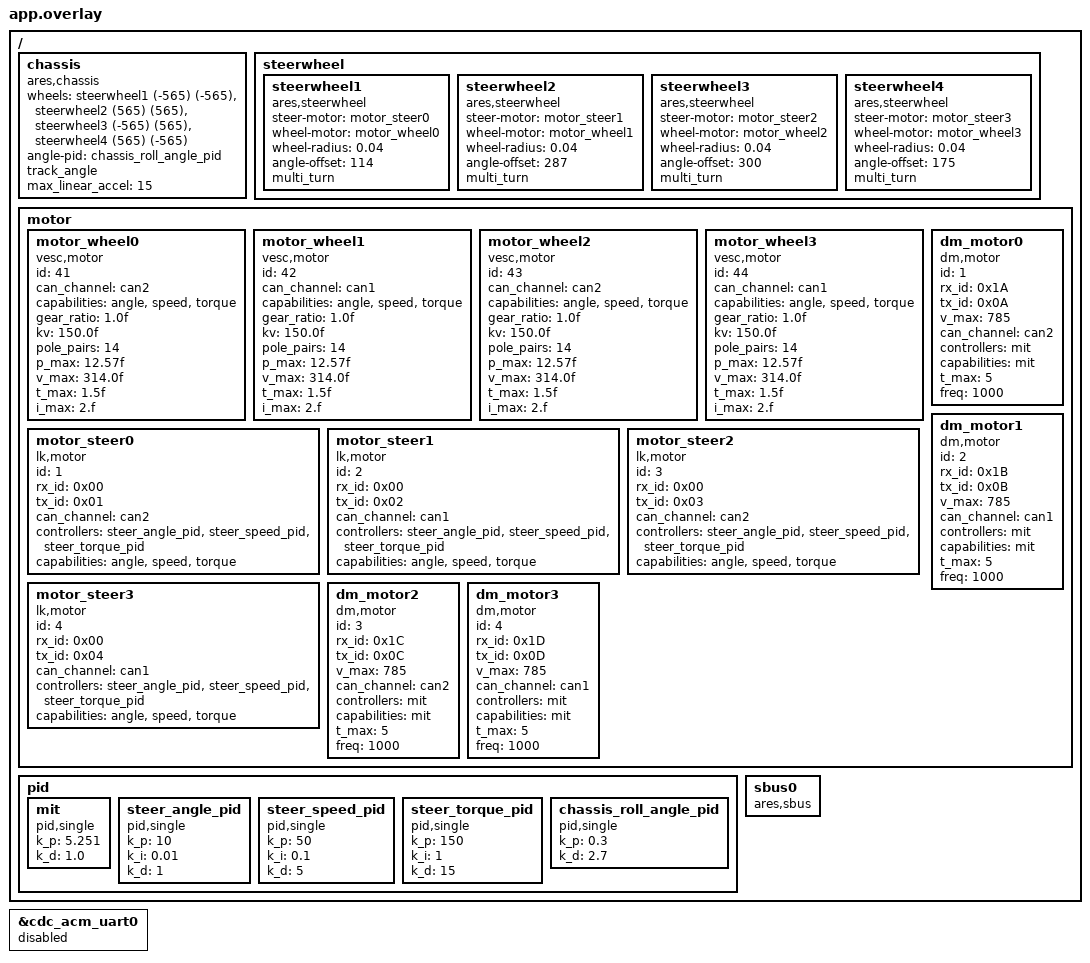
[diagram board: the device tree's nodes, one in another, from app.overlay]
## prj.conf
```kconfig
CONFIG_CMSIS_DSP=y
CONFIG_CMSIS_DSP_CONTROLLER=y
CONFIG_CMSIS_DSP_FASTMATH=y

CONFIG_MOTOR=y
CONFIG_MOTOR_COMMON=y
CONFIG_MOTOR_DM=y
CONFIG_MOTOR_VESC=y
CONFIG_MOTOR_LK=y
CONFIG_MOTOR_LOG_LEVEL=4
CONFIG_CAN=y
CONFIG_MOTOR_INIT_PRIORITY=90

CONFIG_ARES=y
CONFIG_ARES_SBUS=y
CONFIG_EKF_LIB=y

CONFIG_AUTO_PROBE_GYRO_BIAS=y

CONFIG_CHASSIS=y

CONFIG_DUAL_PROPOSE_PROTOCOL=y
# CONFIG_UART_INTERFACE=y
CONFIG_USB_BULK_INTERFACE=y

# CONFIG_SEGGER_SYSTEMVIEW=y

# CONFIG_TRACING_SYSCALL=n

CONFIG_UDC_DRIVER_LOG_LEVEL_WRN=y
CONFIG_USBD_LOG_LEVEL_WRN=y
```

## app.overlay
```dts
/ {
	chassis: chassis {
		compatible = "ares,chassis";
		status = "okay";
		wheels = <&steerwheel1  (-565) (-565)>,
				<&steerwheel2 (565) (565)>,
				<&steerwheel3 (-565) (565)>,
				<&steerwheel4 (565) (-565)>;
		angle-pid = <&chassis_roll_angle_pid>;
		track_angle;
		max_linear_accel = "15";
	};
	steerwheel {
		steerwheel1: steerwheel1 {
			#wheel-cells = <2>;
			compatible = "ares,steerwheel";
			status = "okay";
			steer-motor = <&motor_steer0>;
			wheel-motor = <&motor_wheel0>;
			wheel-radius = "0.04";
			angle-offset = "114";
			multi_turn;
		};

		steerwheel2: steerwheel2 {
			#wheel-cells = <2>;
			compatible = "ares,steerwheel";
			status = "okay";
			steer-motor = <&motor_steer1>;
			wheel-motor = <&motor_wheel1>;
			wheel-radius = "0.04";
			angle-offset = "287";
			multi_turn;
		};

		steerwheel3: steerwheel3 {
			#wheel-cells = <2>;
			compatible = "ares,steerwheel";
			status = "okay";
			steer-motor = <&motor_steer2>;
			wheel-motor = <&motor_wheel2>;
			wheel-radius = "0.04";
			angle-offset = "300";
			multi_turn;
		};
		steerwheel4: steerwheel4 {
			#wheel-cells = <2>;
			compatible = "ares,steerwheel";
			status = "okay";
			steer-motor = <&motor_steer3>;
			wheel-motor = <&motor_wheel3>;
			wheel-radius = "0.04";
			angle-offset = "175";
			multi_turn;
		};
	};

	motor {
		motor_wheel0: motor_wheel0{
			compatible = "vesc,motor";
            id = <41>;
            can_channel = <&can2>;
            capabilities = "angle", "speed", "torque";
            gear_ratio = "1.0f";
            kv = "150.0f";
            pole_pairs = "14";
            p_max = "12.57f";
            v_max = "314.0f";
            t_max = "1.5f";
            i_max = "2.f";
            status = "okay";
		};

		motor_wheel1: motor_wheel1{
			compatible = "vesc,motor";
            id = <42>;
            can_channel = <&can1>;
            capabilities = "angle", "speed", "torque";
            gear_ratio = "1.0f";
            kv = "150.0f";
            pole_pairs = "14";
            p_max = "12.57f";
            v_max = "314.0f";
            t_max = "1.5f";
            i_max = "2.f";
            status = "okay";
		};

		motor_wheel2: motor_wheel2{
			compatible = "vesc,motor";
            id = <43>;
            can_channel = <&can2>;
            capabilities = "angle", "speed", "torque";
            gear_ratio = "1.0f";
            kv = "150.0f";
            pole_pairs = "14";
            p_max = "12.57f";
            v_max = "314.0f";
            t_max = "1.5f";
            i_max = "2.f";
            status = "okay";
		};
		motor_wheel3: motor_wheel3{
			compatible = "vesc,motor";
            id = <44>;
            can_channel = <&can1>;
            capabilities = "angle", "speed", "torque";
            gear_ratio = "1.0f";
            kv = "150.0f";
            pole_pairs = "14";
            p_max = "12.57f";
            v_max = "314.0f";
            t_max = "1.5f";
            i_max = "2.f";
            status = "okay";
		};
		motor_steer0: motor_steer0{
			compatible = "lk,motor";
			id = <1>;
			rx_id = <0x00>;
			tx_id = <0x01>;
			status = "okay";
			can_channel = <&can2>;
			controllers = <&steer_angle_pid &steer_speed_pid &steer_torque_pid>;
			capabilities = "angle", "speed", "torque";
		};

		motor_steer1: motor_steer1{
			compatible = "lk,motor";
			id = <2>;
			rx_id = <0x00>;
			tx_id = <0x02>;
			status = "okay";
			can_channel = <&can1>;
			controllers = <&steer_angle_pid &steer_speed_pid &steer_torque_pid>;
			capabilities = "angle", "speed", "torque";
		};

		motor_steer2: motor_steer2{
			compatible = "lk,motor";
			id = <3>;
			rx_id = <0x00>;
			tx_id = <0x03>;
			status = "okay";
			can_channel = <&can2>;
			controllers = <&steer_angle_pid &steer_speed_pid &steer_torque_pid>;
			capabilities = "angle", "speed", "torque";
		};
		motor_steer3: motor_steer3{
			compatible = "lk,motor";
			id = <4>;
			rx_id = <0x00>;
			tx_id = <0x04>;
			status = "okay";
			can_channel = <&can1>;
			controllers = <&steer_angle_pid &steer_speed_pid &steer_torque_pid>;
			capabilities = "angle", "speed", "torque";
		};
		dm_motor0: dm_motor0{
			compatible = "dm,motor";
			id = <1>;
			rx_id = <0x1A>;
			tx_id = <0x0A>;
			v_max = "785";
			status = "okay";
			can_channel = <&can2>;
			controllers = <&mit>;
			capabilities = "mit";
			t_max = "5";
			freq = <1000>;
		};
		dm_motor1: dm_motor1{
			compatible = "dm,motor";
			id = <2>;
			rx_id = <0x1B>;
			tx_id = <0x0B>;
			v_max = "785";
			status = "okay";
			can_channel = <&can1>;
			controllers = <&mit>;
			capabilities = "mit";
			t_max = "5";
			freq = <1000>;
		};
		dm_motor2: dm_motor2{
			compatible = "dm,motor";
			id = <3>;
			rx_id = <0x1C>;
			tx_id = <0x0C>;
			v_max = "785";
			status = "okay";
			can_channel = <&can2>;
			controllers = <&mit>;
			capabilities = "mit";
			t_max = "5";
			freq = <1000>;
		};
		dm_motor3: dm_motor3{
			compatible = "dm,motor";
			id = <4>;
			rx_id = <0x1D>;
			tx_id = <0x0D>;
			v_max = "785";
			status = "okay";
			can_channel = <&can1>;
			controllers = <&mit>;
			capabilities = "mit";
			t_max = "5";
			freq = <1000>;
		};
	};

	pid {
		
		mit: mit{
			compatible = "pid,single";
			k_p = "5.251";
			k_d = "1.0";
		};
		steer_angle_pid: steer_angle_pid {
			#controller-cells = <0>;
			compatible = "pid,single";
			k_p = "10";
			k_i = "0.01";
			k_d = "1";
		};
		steer_speed_pid: steer_speed_pid {
			#controller-cells = <0>;
			compatible = "pid,single";
			k_p = "50";
			k_i = "0.1";
			k_d = "5";
		};

		steer_torque_pid: steer_torque_pid {
			#controller-cells = <0>;
			compatible = "pid,single";
			k_p = "150";
			k_i = "1";
			k_d = "15";
			
		};
		chassis_roll_angle_pid: chassis_roll_angle_pid {
			#controller-cells = <0>;
			compatible = "pid,single";
			k_p = "0.3";
			k_d = "2.7";
		};

		
	};
	
	sbus0: sbus0 {
		compatible = "ares,sbus";
		status = "okay";
	};
};
&cdc_acm_uart0 {
	status = "disabled";
};
```

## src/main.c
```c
#include <math.h>
#include <stdbool.h>
#include <stddef.h>
#include <stdint.h>
#include <zephyr/device.h>
#include <zephyr/logging/log.h>
#include <zephyr/kernel.h>
#include <zephyr/drivers/motor.h>
#include <zephyr/drivers/sbus.h>
#include <zephyr/drivers/chassis.h>
#include <ares/board/init.h>
#include <ares/ekf/imu_task.h>
#include <ares/interface/usb/usb_bulk.h>
#include <ares/protocol/dual/dual_protocol.h>
#include <ares/ares_comm.h>
#include <sys/_stdint.h>
// #include "ares/ekf/QuaternionEKF.h"
#include "devices.h"
#include <arm_math.h>

LOG_MODULE_REGISTER(main, LOG_LEVEL_DBG);
#ifndef M_PI
#define M_PI 3.14159265f
#endif

int pub_cnt = 0;
#define CHASSIS_SRC_SBUS

// void Sensor_update_cb(QEKF_INS_t *QEKF)
// {
// 	struct pos_data pos = {0};

// 	pos.accel[0] = QEKF->Accel[X];
// 	pos.accel[1] = QEKF->Accel[Y];
// 	pos.accel[2] = QEKF->Accel[Z];
// 	pos.Yaw = QEKF->Yaw;

// 	if (pub_cnt++ % 2) {
// 		// chassis_update_sensor(chassis, &pos);
// 	}
// }

int rank[4] = {1, 1, -1, -1};
bool ups[4] = {true, true, true, true};
const struct device *dmmotor[4];
void run()
{
	for (int id = 0; id < 4; id++) {
		motor_set_mit(dmmotor[id], 10.0f, -50.0f * rank[id], 0.0);
		ups[id] = true;
		k_sleep(K_USEC(130));
	}
}
void lift(int id, bool up)
{
	if (up && (!ups[id])) {
		motor_set_mit(dmmotor[id], 10.0f, 0.0f * rank[id], 0.0);
		ups[id] = true;
	} else if ((!up) && (ups[id])) {
		motor_set_mit(dmmotor[id], 10.0f, -800.0f * rank[id], 0.0);
		ups[id] = false;
	}
	k_sleep(K_USEC(130));
}

void console_feedback(void *arg1, void *arg2, void *arg3)
{
	float angvel = 0;
	int cnt = 0;
	bool zeroed = false;

	while (1) {
		k_msleep(5);
		// chassis_set_static(chassis, false);
		// chassis_set_speed(chassis,  2.5f, 2.5f);
#ifdef CHASSIS_SRC_SBUS
		if (sbus_get_percent(sbus, 4) > 0.5f) {
			lift(0, false);
			lift(1, false);
			lift(2, false);
			lift(3, false);

		} else if (sbus_get_percent(sbus, 4) < -0.5f) {
			run();
		}
		if (sbus_get_percent(sbus, 5) > 0.5f) {
			lift(2, false);
			lift(1, false);
		} else if (sbus_get_percent(sbus, 5) < -0.5f) {
			lift(2, true);
			lift(1, true);
		}
		if (sbus_get_percent(sbus, 6) > 0.5f) {
			lift(0, false);
			lift(3, false);
		} else if (sbus_get_percent(sbus, 6) < -0.5f) {
			lift(0, true);
			lift(3, true);
		}
		angvel = -sbus_get_percent(sbus, 0);
		float X = -sbus_get_percent(sbus, 3);
		float Y = -sbus_get_percent(sbus, 1);
		float linear_magnitude = sqrtf(X * X + Y * Y);
		bool in_deadzone = ((linear_magnitude < 0.06f) && (fabsf(angvel) < 0.06f));
		if (linear_magnitude < 0.06f) {
			X = 0;
			Y = 0;
		}
		if (in_deadzone) {
			chassis_set_static(chassis, true);
			zeroed = true;
		} else {
			chassis_set_static(chassis, false);
			chassis_set_speed(chassis, -X * 1.0f, Y * 1.0f);
			chassis_set_gyro(chassis, angvel * 10.0f);
			zeroed = false;
		}

		// if (cnt++ % 500 == 0) {
		// 		// LOG_INF("Manual: X=%.1f Y=%.1f Gyro=%.1f", (double)X, (double)Y,
		// 		// 	(double)angvel);
		// 		LOG_INF("Chassis: X=%.1f Y=%.1f Gyro=%.1f",
		// (double)sbus_get_percent(sbus, 4), (double)sbus_get_percent(sbus, 5),
		// (double)sbus_get_percent(sbus, 6));

		// }
#endif
	}
}

K_THREAD_DEFINE(feedback_thread, 4096, console_feedback, NULL, NULL, NULL, 2, 0, 100);
uint32_t log_cnt;

int main(void)
{
	k_msleep(2000);

	dmmotor[0] = dm_motor1;
	dmmotor[1] = dm_motor2;
	dmmotor[2] = dm_motor3;
	dmmotor[3] = dm_motor4;
	motor_control(dm_motor1, ENABLE_MOTOR);
	motor_control(dm_motor2, ENABLE_MOTOR);
	motor_control(dm_motor3, ENABLE_MOTOR);
	motor_control(dm_motor4, ENABLE_MOTOR);

	motor_set_mode(dm_motor1, MIT);
	motor_set_mode(dm_motor2, MIT);
	motor_set_mode(dm_motor3, MIT);
	motor_set_mode(dm_motor4, MIT);

	k_msleep(2000);
	motor_control(wheel_motor1, ENABLE_MOTOR);
	motor_control(wheel_motor2, ENABLE_MOTOR);
	motor_control(wheel_motor3, ENABLE_MOTOR);
	motor_control(wheel_motor4, ENABLE_MOTOR);
	k_msleep(100); // 等待电机使能
	motor_set_mode(wheel_motor1, ML_SPEED);
	motor_set_mode(wheel_motor2, ML_SPEED);
	motor_set_mode(wheel_motor3, ML_SPEED);
	motor_set_mode(wheel_motor4, ML_SPEED);
	motor_control(steer_motor1, ENABLE_MOTOR);
	motor_control(steer_motor2, ENABLE_MOTOR);
	motor_control(steer_motor3, ENABLE_MOTOR);
	motor_control(steer_motor4, ENABLE_MOTOR);
	chassis_set_enabled(chassis, false);
	// IMU_Sensor_trig_init(accel_dev, gyro_dev);
	k_msleep(100);
	// IMU_Sensor_set_update_cb(Sensor_update_cb);
	chassis_set_enabled(chassis, true);
	chassis_set_gyro(chassis, 0);

	while (1) {
		k_msleep(2000);
	}

	return 0;
}
```

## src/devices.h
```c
#include <zephyr/device.h>
#include <zephyr/drivers/gpio.h>

/* Devicetree */
// #define ACCEL_NODE DT_NODELABEL(bmi08x_accel)
// const struct device *accel_dev = DEVICE_DT_GET(ACCEL_NODE);

// #define GYRO_NODE DT_NODELABEL(bmi08x_gyro)
// const struct device *gyro_dev = DEVICE_DT_GET(GYRO_NODE);



#define WHEELMOTOR1_NODE DT_NODELABEL(motor_wheel0)
#define WHEELMOTOR2_NODE DT_NODELABEL(motor_wheel1)
#define WHEELMOTOR3_NODE DT_NODELABEL(motor_wheel2)
#define WHEELMOTOR4_NODE DT_NODELABEL(motor_wheel3)

#define STEERMOTOR1_NODE DT_NODELABEL(motor_steer0)
#define STEERMOTOR2_NODE DT_NODELABEL(motor_steer1)
#define STEERMOTOR3_NODE DT_NODELABEL(motor_steer2)
#define STEERMOTOR4_NODE DT_NODELABEL(motor_steer3)

#define DMOTOR_NODE1 DT_NODELABEL(dm_motor0)
#define DMOTOR_NODE2 DT_NODELABEL(dm_motor1)
#define DMOTOR_NODE3 DT_NODELABEL(dm_motor2)
#define DMOTOR_NODE4 DT_NODELABEL(dm_motor3)

#define CHASSIS_NODE DT_NODELABEL(chassis)

const struct device *wheel_motor1 = DEVICE_DT_GET(WHEELMOTOR1_NODE);
const struct device *wheel_motor2 = DEVICE_DT_GET(WHEELMOTOR2_NODE);
const struct device *wheel_motor3 = DEVICE_DT_GET(WHEELMOTOR3_NODE);
const struct device *wheel_motor4 = DEVICE_DT_GET(WHEELMOTOR4_NODE);

const struct device *steer_motor1 = DEVICE_DT_GET(STEERMOTOR1_NODE);
const struct device *steer_motor2 = DEVICE_DT_GET(STEERMOTOR2_NODE);
const struct device *steer_motor3 = DEVICE_DT_GET(STEERMOTOR3_NODE);
const struct device *steer_motor4 = DEVICE_DT_GET(STEERMOTOR4_NODE);

const struct device *dm_motor1 = DEVICE_DT_GET(DMOTOR_NODE1);
const struct device *dm_motor2 = DEVICE_DT_GET(DMOTOR_NODE2);
const struct device *dm_motor3 = DEVICE_DT_GET(DMOTOR_NODE3);
const struct device *dm_motor4 = DEVICE_DT_GET(DMOTOR_NODE4);

const struct device *chassis = DEVICE_DT_GET(CHASSIS_NODE);

#define SBUS_NODE DT_NODELABEL(sbus0)
const struct device *sbus = DEVICE_DT_GET(SBUS_NODE);
```
